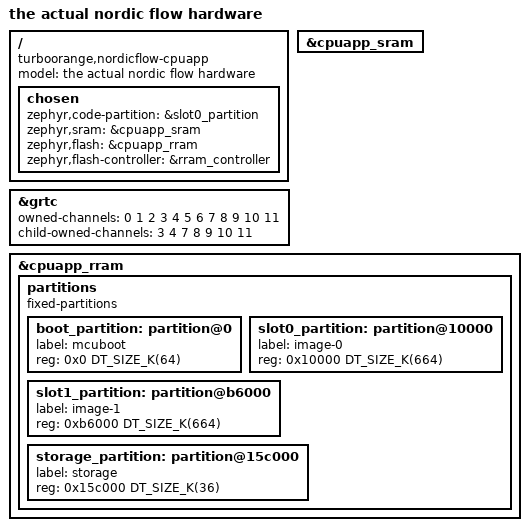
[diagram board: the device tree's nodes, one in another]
/dts-v1/;

#include <nordic/nrf54l15_cpuapp.dtsi>
#include "nordicflow-pinctrl.dtsi"

/ {
	model = "the actual nordic flow hardware";
	compatible = "turboorange,nordicflow-cpuapp";

	chosen {
		zephyr,code-partition = &slot0_partition;
		zephyr,sram = &cpuapp_sram;
		zephyr,flash = &cpuapp_rram;
		zephyr,flash-controller = &rram_controller;
	};
};

&grtc {
	owned-channels = <0 1 2 3 4 5 6 7 8 9 10 11>;
	/* Channels 7-11 reserved for Zero Latency IRQs, 3-4 for FLPR */
	child-owned-channels = <3 4 7 8 9 10 11>;
	status = "okay";
};

&cpuapp_sram {
	status = "okay";
};

&cpuapp_rram {
	partitions {
		compatible = "fixed-partitions";
		#address-cells = <1>;
		#size-cells = <1>;

		boot_partition: partition@0 {
			label = "mcuboot";
			reg = <0x0 DT_SIZE_K(64)>;
		};

		slot0_partition: partition@10000 {
			label = "image-0";
			reg = <0x10000 DT_SIZE_K(664)>;
		};

		slot1_partition: partition@b6000 {
			label = "image-1";
			reg = <0xb6000 DT_SIZE_K(664)>;
		};

		storage_partition: partition@15c000 {
			label = "storage";
			reg = <0x15c000 DT_SIZE_K(36)>;
		};
	};
};
